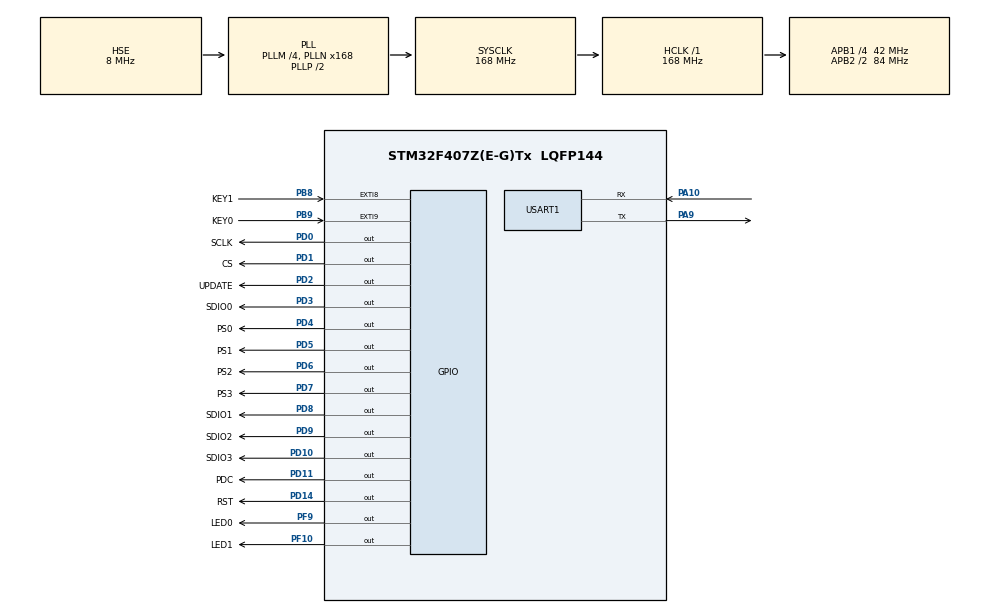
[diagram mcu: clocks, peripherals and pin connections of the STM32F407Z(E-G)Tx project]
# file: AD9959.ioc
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Mcu.Family=STM32F4
Mcu.Name=STM32F407Z(E-G)Tx
Mcu.Package=LQFP144
NVIC.EXTI9_5_IRQn=true\:0\:0\:false\:false\:true\:true\:true\:true
NVIC.PriorityGroup=NVIC_PRIORITYGROUP_4
PA10.Mode=Asynchronous
PA10.Signal=USART1_RX
PA13.Mode=Serial_Wire
PA13.Signal=SYS_JTMS-SWDIO
PA14.Mode=Serial_Wire
PA14.Signal=SYS_JTCK-SWCLK
PA9.Mode=Asynchronous
PA9.Signal=USART1_TX
PB8.GPIO_Label=KEY1
PB8.GPIO_ModeDefaultEXTI=GPIO_MODE_IT_FALLING
PB8.GPIO_PuPd=GPIO_PULLUP
PB8.Signal=GPXTI8
PB9.GPIO_Label=KEY0
PB9.GPIO_ModeDefaultEXTI=GPIO_MODE_IT_FALLING
PB9.GPIO_PuPd=GPIO_PULLUP
PB9.Signal=GPXTI9
PD0.GPIO_Label=SCLK
PD0.GPIO_ModeDefaultOutputPP=GPIO_MODE_OUTPUT_PP
PD0.GPIO_PuPd=GPIO_PULLDOWN
PD0.GPIO_Speed=GPIO_SPEED_FREQ_HIGH
PD0.PinState=GPIO_PIN_RESET
PD0.Signal=GPIO_Output
PD1.GPIO_Label=CS
PD1.GPIO_ModeDefaultOutputPP=GPIO_MODE_OUTPUT_PP
PD1.GPIO_PuPd=GPIO_PULLDOWN
PD1.GPIO_Speed=GPIO_SPEED_FREQ_HIGH
PD1.PinState=GPIO_PIN_RESET
PD1.Signal=GPIO_Output
PD10.GPIO_Label=SDIO3
PD10.GPIO_ModeDefaultOutputPP=GPIO_MODE_OUTPUT_PP
PD10.GPIO_PuPd=GPIO_PULLDOWN
PD10.GPIO_Speed=GPIO_SPEED_FREQ_HIGH
PD10.PinState=GPIO_PIN_RESET
PD10.Signal=GPIO_Output
PD11.GPIO_Label=PDC
PD11.GPIO_ModeDefaultOutputPP=GPIO_MODE_OUTPUT_PP
PD11.GPIO_PuPd=GPIO_PULLDOWN
PD11.GPIO_Speed=GPIO_SPEED_FREQ_HIGH
PD11.PinState=GPIO_PIN_RESET
PD11.Signal=GPIO_Output
PD14.GPIO_Label=RST
PD14.GPIO_ModeDefaultOutputPP=GPIO_MODE_OUTPUT_PP
PD14.GPIO_PuPd=GPIO_PULLDOWN
PD14.GPIO_Speed=GPIO_SPEED_FREQ_HIGH
PD14.PinState=GPIO_PIN_RESET
PD14.Signal=GPIO_Output
PD2.GPIO_Label=UPDATE
PD2.GPIO_ModeDefaultOutputPP=GPIO_MODE_OUTPUT_PP
PD2.GPIO_PuPd=GPIO_PULLDOWN
PD2.GPIO_Speed=GPIO_SPEED_FREQ_HIGH
PD2.PinState=GPIO_PIN_RESET
PD2.Signal=GPIO_Output
PD3.GPIO_Label=SDIO0
PD3.GPIO_ModeDefaultOutputPP=GPIO_MODE_OUTPUT_PP
PD3.GPIO_PuPd=GPIO_PULLDOWN
PD3.GPIO_Speed=GPIO_SPEED_FREQ_HIGH
PD3.PinState=GPIO_PIN_RESET
PD3.Signal=GPIO_Output
PD4.GPIO_Label=PS0
PD4.GPIO_ModeDefaultOutputPP=GPIO_MODE_OUTPUT_PP
PD4.GPIO_PuPd=GPIO_PULLDOWN
PD4.GPIO_Speed=GPIO_SPEED_FREQ_HIGH
PD4.PinState=GPIO_PIN_RESET
PD4.Signal=GPIO_Output
PD5.GPIO_Label=PS1
PD5.GPIO_ModeDefaultOutputPP=GPIO_MODE_OUTPUT_PP
PD5.GPIO_PuPd=GPIO_PULLDOWN
PD5.GPIO_Speed=GPIO_SPEED_FREQ_HIGH
PD5.PinState=GPIO_PIN_RESET
PD5.Signal=GPIO_Output
PD6.GPIO_Label=PS2
PD6.GPIO_ModeDefaultOutputPP=GPIO_MODE_OUTPUT_PP
PD6.GPIO_PuPd=GPIO_PULLDOWN
PD6.GPIO_Speed=GPIO_SPEED_FREQ_HIGH
PD6.PinState=GPIO_PIN_RESET
PD6.Signal=GPIO_Output
PD7.GPIO_Label=PS3
PD7.GPIO_ModeDefaultOutputPP=GPIO_MODE_OUTPUT_PP
PD7.GPIO_PuPd=GPIO_PULLDOWN
PD7.GPIO_Speed=GPIO_SPEED_FREQ_HIGH
PD7.PinState=GPIO_PIN_RESET
PD7.Signal=GPIO_Output
PD8.GPIO_Label=SDIO1
PD8.GPIO_ModeDefaultOutputPP=GPIO_MODE_OUTPUT_PP
PD8.GPIO_PuPd=GPIO_PULLDOWN
PD8.GPIO_Speed=GPIO_SPEED_FREQ_HIGH
PD8.PinState=GPIO_PIN_RESET
PD8.Signal=GPIO_Output
PD9.GPIO_Label=SDIO2
PD9.GPIO_ModeDefaultOutputPP=GPIO_MODE_OUTPUT_PP
PD9.GPIO_PuPd=GPIO_PULLDOWN
PD9.GPIO_Speed=GPIO_SPEED_FREQ_HIGH
PD9.PinState=GPIO_PIN_RESET
PD9.Signal=GPIO_Output
PF10.GPIO_Label=LED1
PF10.GPIO_PuPd=GPIO_PULLUP
PF10.GPIO_Speed=GPIO_SPEED_FREQ_HIGH
PF10.PinState=GPIO_PIN_SET
PF10.Signal=GPIO_Output
PF9.GPIO_Label=LED0
PF9.GPIO_PuPd=GPIO_PULLUP
PF9.GPIO_Speed=GPIO_SPEED_FREQ_HIGH
PF9.PinState=GPIO_PIN_SET
PF9.Signal=GPIO_Output
PH0-OSC_IN.Mode=HSE-External-Oscillator
PH0-OSC_IN.Signal=RCC_OSC_IN
PH1-OSC_OUT.Mode=HSE-External-Oscillator
PH1-OSC_OUT.Signal=RCC_OSC_OUT
ProjectManager.HeapSize=0x200
ProjectManager.StackSize=0x400
ProjectManager.TargetToolchain=STM32CubeIDE
RCC.48MHZClocksFreq_Value=84000000
RCC.AHBFreq_Value=168000000
RCC.APB1CLKDivider=RCC_HCLK_DIV4
RCC.APB1Freq_Value=42000000
RCC.APB1TimFreq_Value=84000000
RCC.APB2CLKDivider=RCC_HCLK_DIV2
RCC.APB2Freq_Value=84000000
RCC.APB2TimFreq_Value=168000000
RCC.CortexFreq_Value=168000000
RCC.HCLKFreq_Value=168000000
RCC.HSE_VALUE=8000000
RCC.HSI_VALUE=16000000
RCC.LSE_VALUE=32768
RCC.PLLM=4
RCC.PLLN=168
RCC.PLLSourceVirtual=RCC_PLLSOURCE_HSE
RCC.SYSCLKFreq_VALUE=168000000
RCC.SYSCLKSource=RCC_SYSCLKSOURCE_PLLCLK
RCC.VCOOutputFreq_Value=336000000
USART1.VirtualMode=VM_ASYNC
board=custom

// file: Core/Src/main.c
/* USER CODE BEGIN Header */
/**
 ******************************************************************************
 * @file           : main.c
 * @brief          : Main program body
 ******************************************************************************
 * @attention
 *
 * Copyright (c) 2023 STMicroelectronics.
 * All rights reserved.
 *
 * This software is licensed under terms that can be found in the LICENSE file
 * in the root directory of this software component.
 * If no LICENSE file comes with this software, it is provided AS-IS.
 *
 ******************************************************************************
 */
/* USER CODE END Header */
#include "main.h"
#include "usart.h"
#include "gpio.h"

/* USER CODE BEGIN Includes */
#include "ad9959.h"
#include <stdio.h>

/* USER CODE END Includes */

void SystemClock_Config(void);

int main(void)
{

  /* MCU Configuration--------------------------------------------------------*/

  /* Reset of all peripherals, Initializes the Flash interface and the Systick. */
  HAL_Init();

  /* Configure the system clock */
  SystemClock_Config();

  /* Initialize all configured peripherals */
  MX_GPIO_Init();
  MX_USART1_UART_Init();
  /* USER CODE BEGIN 2 */
  Init_AD9959();

  printf("Initiated!\r\n");
  /* USER CODE END 2 */

  /* Infinite loop */
  /* USER CODE BEGIN WHILE */
  Sweep_Frequency(3, 1, 50000000, 1, 255, 0);
  AD9959_IO_Update();

  while (1)
  {
    /* USER CODE END WHILE */

  }
}

void SystemClock_Config(void)
{
  RCC_OscInitTypeDef RCC_OscInitStruct = {0};
  RCC_ClkInitTypeDef RCC_ClkInitStruct = {0};

  /** Configure the main internal regulator output voltage
   */
  __HAL_RCC_PWR_CLK_ENABLE();
  __HAL_PWR_VOLTAGESCALING_CONFIG(PWR_REGULATOR_VOLTAGE_SCALE1);

  /** Initializes the RCC Oscillators according to the specified parameters
   * in the RCC_OscInitTypeDef structure.
   */
  RCC_OscInitStruct.OscillatorType = RCC_OSCILLATORTYPE_HSE;
  RCC_OscInitStruct.HSEState = RCC_HSE_ON;
  RCC_OscInitStruct.PLL.PLLState = RCC_PLL_ON;
  RCC_OscInitStruct.PLL.PLLSource = RCC_PLLSOURCE_HSE;
  RCC_OscInitStruct.PLL.PLLM = 4;
  RCC_OscInitStruct.PLL.PLLN = 168;
  RCC_OscInitStruct.PLL.PLLP = RCC_PLLP_DIV2;
  RCC_OscInitStruct.PLL.PLLQ = 4;
  if (HAL_RCC_OscConfig(&RCC_OscInitStruct) != HAL_OK)
  {
    Error_Handler();
  }

  /** Initializes the CPU, AHB and APB buses clocks
   */
  RCC_ClkInitStruct.ClockType = RCC_CLOCKTYPE_HCLK | RCC_CLOCKTYPE_SYSCLK | RCC_CLOCKTYPE_PCLK1 | RCC_CLOCKTYPE_PCLK2;
  RCC_ClkInitStruct.SYSCLKSource = RCC_SYSCLKSOURCE_PLLCLK;
  RCC_ClkInitStruct.AHBCLKDivider = RCC_SYSCLK_DIV1;
  RCC_ClkInitStruct.APB1CLKDivider = RCC_HCLK_DIV4;
  RCC_ClkInitStruct.APB2CLKDivider = RCC_HCLK_DIV2;

  if (HAL_RCC_ClockConfig(&RCC_ClkInitStruct, FLASH_LATENCY_5) != HAL_OK)
  {
    Error_Handler();
  }
}

void Error_Handler(void)
{
  __disable_irq();
  while (1)
  {
  }
}
